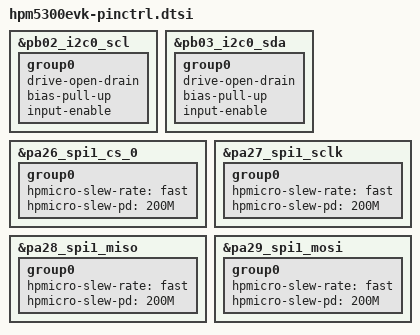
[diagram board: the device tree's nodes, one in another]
/*
 * Copyright (c) 2026 The HPM Zephyr Module Contributors
 * SPDX-License-Identifier: Apache-2.0
 */

#include <hpmicro/hpm5361-icb-pinctrl.dtsi>

/* HPM5300EVK carries the LQFP100 HPM5361ICB1 package. */
&pb02_i2c0_scl {
	group0 {
		drive-open-drain;
		bias-pull-up;
		input-enable;
	};
};

&pb03_i2c0_sda {
	group0 {
		drive-open-drain;
		bias-pull-up;
		input-enable;
	};
};

&pa26_spi1_cs_0 {
	group0 {
		hpmicro-slew-rate = "fast";
		hpmicro-slew-pd = "200M";
	};
};

&pa27_spi1_sclk {
	group0 {
		hpmicro-slew-rate = "fast";
		hpmicro-slew-pd = "200M";
	};
};

&pa28_spi1_miso {
	group0 {
		hpmicro-slew-rate = "fast";
		hpmicro-slew-pd = "200M";
	};
};

&pa29_spi1_mosi {
	group0 {
		hpmicro-slew-rate = "fast";
		hpmicro-slew-pd = "200M";
	};
};
